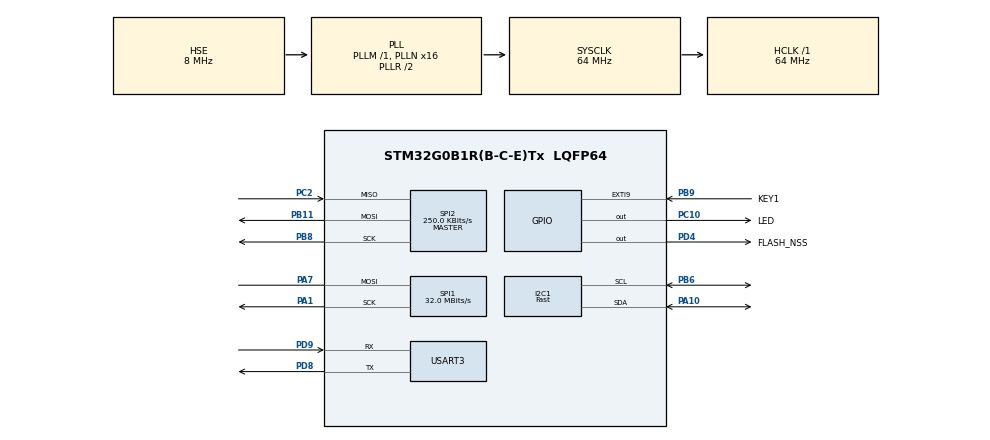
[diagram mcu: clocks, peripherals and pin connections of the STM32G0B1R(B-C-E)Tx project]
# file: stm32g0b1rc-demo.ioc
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Dma.Request0=SPI1_TX
Dma.SPI1_TX.0.Direction=DMA_MEMORY_TO_PERIPH
Dma.SPI1_TX.0.EventEnable=DISABLE
Dma.SPI1_TX.0.Instance=DMA1_Channel1
Dma.SPI1_TX.0.MemDataAlignment=DMA_MDATAALIGN_BYTE
Dma.SPI1_TX.0.MemInc=DMA_MINC_DISABLE
Dma.SPI1_TX.0.Mode=DMA_NORMAL
Dma.SPI1_TX.0.PeriphDataAlignment=DMA_PDATAALIGN_BYTE
Dma.SPI1_TX.0.PeriphInc=DMA_PINC_DISABLE
Dma.SPI1_TX.0.Polarity=HAL_DMAMUX_REQ_GEN_RISING
Dma.SPI1_TX.0.Priority=DMA_PRIORITY_LOW
Dma.SPI1_TX.0.RequestNumber=1
Dma.SPI1_TX.0.SignalID=NONE
Dma.SPI1_TX.0.SyncEnable=DISABLE
Dma.SPI1_TX.0.SyncPolarity=HAL_DMAMUX_SYNC_NO_EVENT
Dma.SPI1_TX.0.SyncRequestNumber=1
Dma.SPI1_TX.0.SyncSignalID=NONE
I2C1.I2C_Speed_Mode=I2C_Fast
I2C1.Timing=0x00C12166
Mcu.Family=STM32G0
Mcu.Name=STM32G0B1R(B-C-E)Tx
Mcu.Package=LQFP64
NVIC.DMA1_Channel1_IRQn=true\:0\:0\:false\:false\:true\:false\:true\:true
NVIC.EXTI4_15_IRQn=true\:0\:0\:false\:false\:true\:true\:true\:true
PA1.GPIO_Speed=GPIO_SPEED_FREQ_VERY_HIGH
PA1.Mode=Simplex_Bidirectional_Master
PA1.PinState=GPIO_PIN_SET
PA1.Signal=SPI1_SCK
PA10.Mode=I2C
PA10.Signal=I2C1_SDA
PA13.Mode=Serial_Wire
PA13.Signal=SYS_SWDIO
PA14-BOOT0.Mode=Serial_Wire
PA14-BOOT0.Signal=SYS_SWCLK
PA7.GPIO_Speed=GPIO_SPEED_FREQ_VERY_HIGH
PA7.Mode=Simplex_Bidirectional_Master
PA7.PinState=GPIO_PIN_SET
PA7.Signal=SPI1_MOSI
PB11.Mode=Full_Duplex_Master
PB11.Signal=SPI2_MOSI
PB6.Mode=I2C
PB6.Signal=I2C1_SCL
PB8.Mode=Full_Duplex_Master
PB8.Signal=SPI2_SCK
PB9.GPIO_Label=KEY1
PB9.GPIO_ModeDefaultEXTI=GPIO_MODE_IT_FALLING
PB9.GPIO_PuPd=GPIO_PULLUP
PB9.Signal=GPXTI9
PC10.GPIO_Label=LED
PC10.PinState=GPIO_PIN_SET
PC10.Signal=GPIO_Output
PC14-OSC32_IN\ (PC14).Mode=LSE-External-Oscillator
PC14-OSC32_IN\ (PC14).Signal=RCC_OSC32_IN
PC15-OSC32_OUT\ (PC15).Mode=LSE-External-Oscillator
PC15-OSC32_OUT\ (PC15).Signal=RCC_OSC32_OUT
PC2.Mode=Full_Duplex_Master
PC2.Signal=SPI2_MISO
PD4.GPIO_Label=FLASH_NSS
PD4.PinState=GPIO_PIN_SET
PD4.Signal=GPIO_Output
PD8.Mode=Asynchronous
PD8.Signal=USART3_TX
PD9.Mode=Asynchronous
PD9.Signal=USART3_RX
PF0-OSC_IN\ (PF0).Mode=HSE-External-Oscillator
PF0-OSC_IN\ (PF0).Signal=RCC_OSC_IN
PF1-OSC_OUT\ (PF1).Mode=HSE-External-Oscillator
PF1-OSC_OUT\ (PF1).Signal=RCC_OSC_OUT
ProjectManager.HeapSize=0x200
ProjectManager.StackSize=0x400
ProjectManager.TargetToolchain=MDK-ARM V5.32
RCC.ADCFreq_Value=64000000
RCC.AHBFreq_Value=64000000
RCC.CortexFreq_Value=64000000
RCC.EXTERNAL_CLOCK_VALUE=48000
RCC.HCLKFreq_Value=64000000
RCC.HSE_VALUE=8000000
RCC.HSI48_VALUE=48000000
RCC.HSI_VALUE=16000000
RCC.PLLN=16
RCC.PLLSourceVirtual=RCC_PLLSOURCE_HSE
RCC.RTCClockSelection=RCC_RTCCLKSOURCE_LSE
RCC.SYSCLKFreq_VALUE=64000000
RCC.SYSCLKSource=RCC_SYSCLKSOURCE_PLLCLK
RCC.USBFreq_Value=48000000
RCC.VCOOutputFreq_Value=128000000
SPI1.CalculateBaudRate=32.0 MBits/s
SPI1.DataSize=SPI_DATASIZE_8BIT
SPI1.Direction=SPI_DIRECTION_1LINE
SPI1.Mode=SPI_MODE_MASTER
SPI1.NSSPMode=SPI_NSS_PULSE_DISABLE
SPI1.VirtualType=VM_MASTER
SPI2.BaudRatePrescaler=SPI_BAUDRATEPRESCALER_256
SPI2.CLKPhase=SPI_PHASE_2EDGE
SPI2.CLKPolarity=SPI_POLARITY_HIGH
SPI2.CalculateBaudRate=250.0 KBits/s
SPI2.DataSize=SPI_DATASIZE_8BIT
SPI2.Direction=SPI_DIRECTION_2LINES
SPI2.Mode=SPI_MODE_MASTER
SPI2.VirtualType=VM_MASTER
USART3.VirtualMode-Asynchronous=VM_ASYNC
VP_RTC_VS_RTC_Activate.Mode=RTC_Enabled
VP_RTC_VS_RTC_Calendar.Mode=RTC_Calendar
VP_SYS_VS_DBSignals.Mode=DisableDeadBatterySignals
board=custom

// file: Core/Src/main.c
/* USER CODE BEGIN Header */
/**
  ******************************************************************************
  * @file           : main.c
  * @brief          : Main program body
  ******************************************************************************
  * @attention
  *
  * Copyright (c) 2025 STMicroelectronics.
  * All rights reserved.
  *
  * This software is licensed under terms that can be found in the LICENSE file
  * in the root directory of this software component.
  * If no LICENSE file comes with this software, it is provided AS-IS.
  *
  ******************************************************************************
  */
/* USER CODE END Header */
#include "main.h"
#include "dma.h"
#include "i2c.h"
#include "rtc.h"
#include "spi.h"
#include "usart.h"
#include "gpio.h"

/* USER CODE BEGIN Includes */
#include "lcd_demo.h"
#include "flash_demo.h"
#include "eeprom_demo.h"
/* USER CODE END Includes */

void SystemClock_Config(void);

int main(void)
{

  /* MCU Configuration--------------------------------------------------------*/

  /* Reset of all peripherals, Initializes the Flash interface and the Systick. */
  HAL_Init();

  /* Configure the system clock */
  SystemClock_Config();

  /* Initialize all configured peripherals */
  MX_GPIO_Init();
  MX_DMA_Init();
  MX_RTC_Init();
  MX_USART3_UART_Init();
  MX_I2C1_Init();
  MX_SPI2_Init();
  MX_SPI1_Init();

  /* Infinite loop */
  /* USER CODE BEGIN WHILE */
	AT24C02_Test();
	flash_demo();
	LCD_DEMO();
  /* USER CODE END 3 */
}

void SystemClock_Config(void)
{
  RCC_OscInitTypeDef RCC_OscInitStruct = {0};
  RCC_ClkInitTypeDef RCC_ClkInitStruct = {0};

  /** Configure the main internal regulator output voltage
  */
  HAL_PWREx_ControlVoltageScaling(PWR_REGULATOR_VOLTAGE_SCALE1);

  /** Configure LSE Drive Capability
  */
  HAL_PWR_EnableBkUpAccess();
  __HAL_RCC_LSEDRIVE_CONFIG(RCC_LSEDRIVE_LOW);

  /** Initializes the RCC Oscillators according to the specified parameters
  * in the RCC_OscInitTypeDef structure.
  */
  RCC_OscInitStruct.OscillatorType = RCC_OSCILLATORTYPE_HSE|RCC_OSCILLATORTYPE_LSE;
  RCC_OscInitStruct.HSEState = RCC_HSE_ON;
  RCC_OscInitStruct.LSEState = RCC_LSE_ON;
  RCC_OscInitStruct.PLL.PLLState = RCC_PLL_ON;
  RCC_OscInitStruct.PLL.PLLSource = RCC_PLLSOURCE_HSE;
  RCC_OscInitStruct.PLL.PLLM = RCC_PLLM_DIV1;
  RCC_OscInitStruct.PLL.PLLN = 16;
  RCC_OscInitStruct.PLL.PLLP = RCC_PLLP_DIV2;
  RCC_OscInitStruct.PLL.PLLQ = RCC_PLLQ_DIV2;
  RCC_OscInitStruct.PLL.PLLR = RCC_PLLR_DIV2;
  if (HAL_RCC_OscConfig(&RCC_OscInitStruct) != HAL_OK)
  {
    Error_Handler();
  }

  /** Initializes the CPU, AHB and APB buses clocks
  */
  RCC_ClkInitStruct.ClockType = RCC_CLOCKTYPE_HCLK|RCC_CLOCKTYPE_SYSCLK
                              |RCC_CLOCKTYPE_PCLK1;
  RCC_ClkInitStruct.SYSCLKSource = RCC_SYSCLKSOURCE_PLLCLK;
  RCC_ClkInitStruct.AHBCLKDivider = RCC_SYSCLK_DIV1;
  RCC_ClkInitStruct.APB1CLKDivider = RCC_HCLK_DIV1;

  if (HAL_RCC_ClockConfig(&RCC_ClkInitStruct, FLASH_LATENCY_2) != HAL_OK)
  {
    Error_Handler();
  }
}

void Error_Handler(void)
{
  __disable_irq();
  while (1)
  {
  }
}
